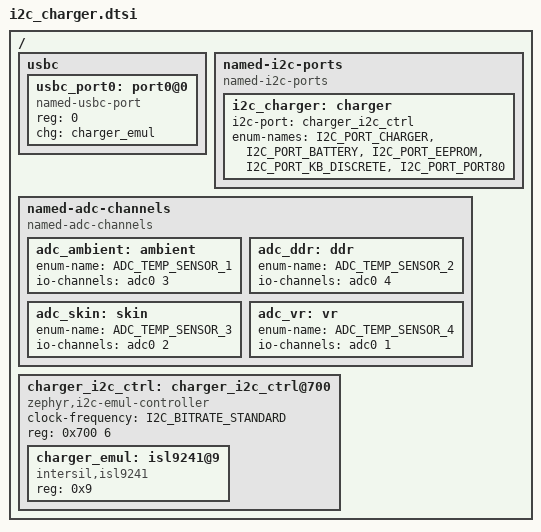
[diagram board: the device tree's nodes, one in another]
/* Copyright 2024 The ChromiumOS Authors
 * Use of this source code is governed by a BSD-style license that can be
 * found in the LICENSE file.
 */

/ {
	usbc {
		#address-cells = <1>;
		#size-cells = <0>;

		usbc_port0: port0@0 {
			compatible = "named-usbc-port";
			reg = <0>;
			chg = <&charger_emul>;
	        };
	};

	named-i2c-ports {
		compatible = "named-i2c-ports";

		i2c_charger: charger {
			i2c-port = <&charger_i2c_ctrl>;
			enum-names = "I2C_PORT_CHARGER",
				"I2C_PORT_BATTERY",
				"I2C_PORT_EEPROM",
				"I2C_PORT_KB_DISCRETE",
				"I2C_PORT_PORT80";
		};
	};

	named-adc-channels {
		compatible = "named-adc-channels";

		adc_ambient: ambient {
			enum-name = "ADC_TEMP_SENSOR_1";
			io-channels = <&adc0 3>;
		};
		adc_ddr: ddr {
			enum-name = "ADC_TEMP_SENSOR_2";
			io-channels = <&adc0 4>;
		};
		adc_skin: skin {
			enum-name = "ADC_TEMP_SENSOR_3";
			io-channels = <&adc0 2>;
		};
		adc_vr: vr {
			enum-name = "ADC_TEMP_SENSOR_4";
			io-channels = <&adc0 1>;
		};
	};

	charger_i2c_ctrl: charger_i2c_ctrl@700 {
		status = "okay";
		compatible = "zephyr,i2c-emul-controller";
		clock-frequency = <I2C_BITRATE_STANDARD>;
		#address-cells = <1>;
		#size-cells = <0>;
		reg = <0x700 6>;

	        charger_emul: isl9241@9 {
		        compatible = "intersil,isl9241";
		        status = "okay";
		        reg = <0x9>;
	        };

		/* kb_discrete: ite-it8801@39 {
			compatible = "ite,it8801","cros,i2c-mock";
			reg = <0x39>;
		};*/
	};
};
